VERSION ""

NS_ :

BS_:

BU_:
VAL_TABLE_ FMI 31 "Not available" 19 "Received network data in error" 18 "Below normal (moderately severe)" 17 "Below normal (least severe)" 16 "Above normal (moderately severe)" 15 "Above normal (least severe)" 14 "Special intstructions" 13 "Out of calibration" 12 "Bad intelligent device" 11 "Root cause not known" 10 "Abnormal rate of change" 9 "Abnormal update rate" 8 "Abnormal frequency" 7 "Mechanical system not responding" 6 "Current above normal" 5 "Current below normal" 4 "Voltage below normal" 3 "Voltage above normal" 2 "Data erratic" 1 "Below normal (most severe)" 0 "Above normal (most severe)" ;

BO_ 3221225472 VECTOR__INDEPENDENT_SIG_MSG: 0 Vector__XXX
 SG_ DslPrtcltFltrActvRgnrtnInhbtdDTE : 0|2@1+ (1,0) [0|3] "" Vector__XXX
 SG_ DTC1 : 0|32@1+ (1,0) [0|4294967295] "" Vector__XXX
 SG_ TestIdentifier : 0|8@1+ (1,0) [1|64] "" Vector__XXX
 SG_ TestIdentifier : 0|8@1+ (1,0) [1|64] "" Vector__XXX

BO_ 257 CANSTD2: 8 Vector__XXX

BO_ 2147548747 CANEXT4: 2 Vector__XXX
 SG_ EXT4_sig : 0|2@1+ (1,0) [0|0] "" Vector__XXX

BO_ 2147483904 CANEXT3: 8 Vector__XXX
 SG_ EXT3_sig : 0|8@1+ (1,0) [0|0] "" Vector__XXX

BO_ 256 CANSTD1: 8 Vector__XXX
 SG_ STD1_sig : 0|2@1+ (1,0) [0|0] "" Vector__XXX

BO_ 2298366974 CANEXT2: 2 Vector__XXX
 SG_ EXT2_sig : 0|2@1+ (1,0) [0|0] "" Vector__XXX

BO_ 2224684798 CANEXT1: 8 Vector__XXX
 SG_ EXT1_sig : 0|8@1+ (1,0) [0|0] "" Vector__XXX

BO_ 2348941054 TC1: 8 Vector__XXX
 SG_ TransMode8 : 62|2@1+ (1,0) [0|3] "" Vector__XXX
 SG_ TransMode7 : 60|2@1+ (1,0) [0|3] "" Vector__XXX
 SG_ TransMode6 : 58|2@1+ (1,0) [0|3] "" Vector__XXX
 SG_ TransMode5 : 56|2@1+ (1,0) [0|3] "" Vector__XXX
 SG_ TrnsShftSlectorDisplayModeSwitch : 54|2@1+ (1,0) [0|3] "" Vector__XXX
 SG_ TransRequestedLaunchGear : 50|4@1+ (1,0) [0|15] "" Vector__XXX
 SG_ TransMode4 : 46|2@1+ (1,0) [0|3] "" Vector__XXX
 SG_ TransMode3 : 44|2@1+ (1,0) [0|3] "" Vector__XXX
 SG_ TransMode2 : 42|2@1+ (1,0) [0|3] "" Vector__XXX
 SG_ TransMode1 : 40|2@1+ (1,0) [0|3] "" Vector__XXX
 SG_ DisengageDiffLockRqCentralRear : 36|2@1+ (1,0) [0|3] "" Vector__XXX
 SG_ DisengageDiffLockRqCentralFront : 34|2@1+ (1,0) [0|3] "" Vector__XXX
 SG_ DisengageDiffLockRqCentral : 32|2@1+ (1,0) [0|3] "" Vector__XXX
 SG_ DisengageDiffLockRqRearAxle2 : 30|2@1+ (1,0) [0|3] "" Vector__XXX
 SG_ DisengageDiffLockRqRearAxle1 : 28|2@1+ (1,0) [0|3] "" Vector__XXX
 SG_ DisengageDiffLockRqFrontAxle2 : 26|2@1+ (1,0) [0|3] "" Vector__XXX
 SG_ DisengageDiffLockRqFrontAxle1 : 24|2@1+ (1,0) [0|3] "" Vector__XXX
 SG_ TransRequestedGear : 16|8@1+ (1,-125) [-125|125] "" Vector__XXX
 SG_ RequestedPercentClutchSlip : 8|8@1+ (1,0) [0|100] "%" Vector__XXX
 SG_ TransReverseGearShiftInhibitRq : 6|2@1+ (1,0) [0|3] "" Vector__XXX
 SG_ DisengageDrivelineRq : 4|2@1+ (1,0) [0|3] "" Vector__XXX
 SG_ TrnsTrqeConverterLockupDisableRq : 2|2@1+ (1,0) [0|3] "" Vector__XXX
 SG_ TransGearShiftInhibitRq : 0|2@1+ (1,0) [0|3] "" Vector__XXX

BO_ 2358902526 JLCM: 8 Vector__XXX
 SG_ Joystick3Lamp10Cmd : 58|2@1+ (1,0) [0|3] "" Vector__XXX
 SG_ Joystick3Lamp9Cmd : 56|2@1+ (1,0) [0|3] "" Vector__XXX
 SG_ Joystick3Lamp8Cmd : 54|2@1+ (1,0) [0|3] "" Vector__XXX
 SG_ Joystick3Lamp7Cmd : 52|2@1+ (1,0) [0|3] "" Vector__XXX
 SG_ Joystick3Lamp6Cmd : 50|2@1+ (1,0) [0|3] "" Vector__XXX
 SG_ Joystick3Lamp5Cmd : 48|2@1+ (1,0) [0|3] "" Vector__XXX
 SG_ Joystick3Lamp4Cmd : 46|2@1+ (1,0) [0|3] "" Vector__XXX
 SG_ Joystick3Lamp3Cmd : 44|2@1+ (1,0) [0|3] "" Vector__XXX
 SG_ Joystick3Lamp2Cmd : 42|2@1+ (1,0) [0|3] "" Vector__XXX
 SG_ Joystick3Lamp1Cmd : 40|2@1+ (1,0) [0|3] "" Vector__XXX
 SG_ Joystick2Lamp10Cmd : 38|2@1+ (1,0) [0|3] "" Vector__XXX
 SG_ Joystick2Lamp9Cmd : 36|2@1+ (1,0) [0|3] "" Vector__XXX
 SG_ Joystick2Lamp8Cmd : 34|2@1+ (1,0) [0|3] "" Vector__XXX
 SG_ Joystick2Lamp7Cmd : 32|2@1+ (1,0) [0|3] "" Vector__XXX
 SG_ Joystick2Lamp6Cmd : 30|2@1+ (1,0) [0|3] "" Vector__XXX
 SG_ Joystick2Lamp5Cmd : 28|2@1+ (1,0) [0|3] "" Vector__XXX
 SG_ Joystick2Lamp4Cmd : 26|2@1+ (1,0) [0|3] "" Vector__XXX
 SG_ Joystick2Lamp3Cmd : 24|2@1+ (1,0) [0|3] "" Vector__XXX
 SG_ Joystick2Lamp2Cmd : 22|2@1+ (1,0) [0|3] "" Vector__XXX
 SG_ Joystick2Lamp1Cmd : 20|2@1+ (1,0) [0|3] "" Vector__XXX
 SG_ Joystick1Lamp10Cmd : 18|2@1+ (1,0) [0|3] "" Vector__XXX
 SG_ Joystick1Lamp9Cmd : 16|2@1+ (1,0) [0|3] "" Vector__XXX
 SG_ Joystick1Lamp8Cmd : 14|2@1+ (1,0) [0|3] "" Vector__XXX
 SG_ Joystick1Lamp7Cmd : 12|2@1+ (1,0) [0|3] "" Vector__XXX
 SG_ Joystick1Lamp6Cmd : 10|2@1+ (1,0) [0|3] "" Vector__XXX
 SG_ Joystick1Lamp5Cmd : 8|2@1+ (1,0) [0|3] "" Vector__XXX
 SG_ Joystick1Lamp4Cmd : 6|2@1+ (1,0) [0|3] "" Vector__XXX
 SG_ Joystick1Lamp3Cmd : 4|2@1+ (1,0) [0|3] "" Vector__XXX
 SG_ Joystick1Lamp2Cmd : 2|2@1+ (1,0) [0|3] "" Vector__XXX
 SG_ Joystick1Lamp1Cmd : 0|2@1+ (1,0) [0|3] "" Vector__XXX

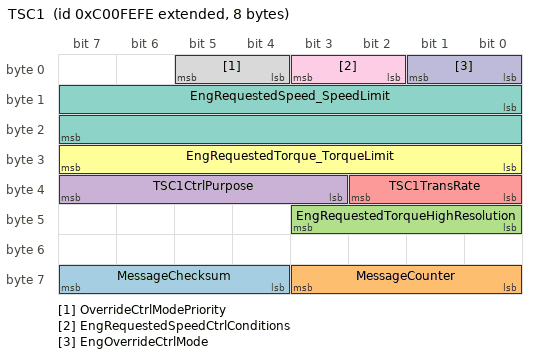
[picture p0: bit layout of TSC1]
BO_ 2348875518 TSC1: 8 Vector__XXX
 SG_ MessageChecksum : 60|4@1+ (1,0) [0|15] "" Vector__XXX
 SG_ MessageCounter : 56|4@1+ (1,0) [0|15] "" Vector__XXX
 SG_ EngRequestedTorqueHighResolution : 40|4@1+ (1,0) [0|0.875] "%" Vector__XXX
 SG_ TSC1CtrlPurpose : 35|5@1+ (1,0) [0|31] "" Vector__XXX
 SG_ TSC1TransRate : 32|3@1+ (1,0) [0|7] "" Vector__XXX
 SG_ EngRequestedTorque_TorqueLimit : 24|8@1+ (1,-125) [-125|125] "%" Vector__XXX
 SG_ EngRequestedSpeed_SpeedLimit : 8|16@1+ (1,0) [0|8031.875] "rpm" Vector__XXX
 SG_ OverrideCtrlModePriority : 4|2@1+ (1,0) [0|3] "" Vector__XXX
 SG_ EngRequestedSpeedCtrlConditions : 2|2@1+ (1,0) [0|3] "" Vector__XXX
 SG_ EngOverrideCtrlMode : 0|2@1+ (1,0) [0|3] "" Vector__XXX

BO_ 2566802430 TCFG2: 2 Vector__XXX
 SG_ TransTorqueLimit : 0|16@1+ (1,0) [0|64255] "Nm" Vector__XXX

BO_ 2566841342 EC1: 39 Vector__XXX
 SG_ SupportTSC1CtrlPurposeGroup4 : 304|8@1+ (1,0) [0|255] "" Vector__XXX
 SG_ SupportTSC1CtrlPurposeGroup3 : 296|8@1+ (1,0) [0|255] "" Vector__XXX
 SG_ SupportTSC1CtrlPurposeGroup2 : 288|8@1+ (1,0) [0|255] "" Vector__XXX
 SG_ SupportTSC1CtrlPurposeGroup1 : 280|8@1+ (1,0) [0|255] "" Vector__XXX
 SG_ SupportVariableRateTSC1Message : 272|8@1+ (1,0) [0|255] "" Vector__XXX
 SG_ EngDefaultTorqueLimit : 256|16@1+ (1,0) [0|64255] "Nm" Vector__XXX
 SG_ EngMomentOfInertia : 240|16@1+ (0.004,0) [0|262.14] "kg-m^2" Vector__XXX
 SG_ EngExRngRqstdSpdCtrlRngUpprLimit : 224|16@1+ (0.125,0) [0|8031.875] "rpm" Vector__XXX
 SG_ EngRqstdTrqueCtrlRangeUpperLimit : 216|8@1+ (1,-125) [-125|125] "%" Vector__XXX
 SG_ EngRqstdTrqueCtrlRangeLowerLimit : 208|8@1+ (1,-125) [-125|125] "%" Vector__XXX
 SG_ EngRqstdSpeedCtrlRangeUpperLimit : 200|8@1+ (10,0) [0|2500] "rpm" Vector__XXX
 SG_ EngRqstdSpeedCtrlRangeLowerLimit : 192|8@1+ (10,0) [0|2500] "rpm" Vector__XXX
 SG_ EngMaxMomentaryOverrideTimeLimit : 184|8@1+ (0.1,0) [0|25] "s" Vector__XXX
 SG_ EngMxMmentaryOverrideSpeedPoint7 : 168|16@1+ (0.125,0) [0|8031.875] "rpm" Vector__XXX
 SG_ EngReferenceTorque : 152|16@1+ (1,0) [0|64255] "Nm" Vector__XXX
 SG_ EngGain : 136|16@1+ (0.00078126215858688,0) [0|50.2] "%/rpm" Vector__XXX
 SG_ EngSpeedAtHighIdlePoint6 : 120|16@1+ (0.125,0) [0|8031.875] "rpm" Vector__XXX
 SG_ EngPercentTorqueAtPoint5 : 112|8@1+ (1,-125) [-125|125] "%" Vector__XXX
 SG_ EngSpeedAtPoint5 : 96|16@1+ (0.125,0) [0|8031.875] "rpm" Vector__XXX
 SG_ EngPercentTorqueAtPoint4 : 88|8@1+ (1,-125) [-125|125] "%" Vector__XXX
 SG_ EngSpeedAtPoint4 : 72|16@1+ (0.125,0) [0|8031.875] "rpm" Vector__XXX
 SG_ EngPercentTorqueAtPoint3 : 64|8@1+ (1,-125) [-125|125] "%" Vector__XXX
 SG_ EngSpeedAtPoint3 : 48|16@1+ (0.125,0) [0|8031.875] "rpm" Vector__XXX
 SG_ EngPercentTorqueAtPoint2 : 40|8@1+ (1,-125) [-125|125] "%" Vector__XXX
 SG_ EngSpeedAtPoint2 : 24|16@1+ (0.125,0) [0|8031.875] "rpm" Vector__XXX
 SG_ EngPercentTorqueAtIdlePoint1 : 16|8@1+ (1,-125) [-125|125] "%" Vector__XXX
 SG_ EngSpeedAtIdlePoint1 : 0|16@1+ (0.125,0) [0|8031.875] "rpm" Vector__XXX

BO_ 2564030206 DM19: 20 Vector__XXX
 SG_ CalibrationID4 : 128|32@1+ (1,0) [0|4294967295] "" Vector__XXX
 SG_ CalibrationID3 : 96|32@1+ (1,0) [0|4294967295] "" Vector__XXX
 SG_ CalibrationID2 : 64|32@1+ (1,0) [0|4294967295] "" Vector__XXX
 SG_ CalibrationID1 : 32|32@1+ (1,0) [0|4294967295] "" Vector__XXX
 SG_ CalibrationVerificationNumber : 0|32@1+ (1,0) [0|4294967295] "" Vector__XXX

CM_ BO_ 3221225472 "This is a message for not used signals, created by Vector CANdb++ DBC OLE DB Provider.";
CM_ SG_ 3221225472 DslPrtcltFltrActvRgnrtnInhbtdDTE "Indicates the state of diesel particulate filter active regeneration inhibition due to the engine not being warmed up.";
CM_ SG_ 3221225472 DTC1 "Diagnostic Trouble CodeDiagnostic Trouble CodeDiagnostic Trouble CodeDiagnostic Trouble CodeDiagnostic Trouble CodeDiagnostic Trouble CodeDiagnostic Trouble CodeDiagnostic Trouble CodeDiagnostic Trouble CodeDiagnostic Trouble CodeDiagnostic Trouble CodeDiagnostic Trouble CodeDiagnostic Trouble CodeDiagnostic Trouble CodeDiagnostic Trouble CodeDiagnostic Trouble CodeDiagnostic Trouble CodeDiagnostic Trouble CodeDiagnostic Trouble CodeDiagnostic Trouble CodeDiagnostic Trouble CodeDiagnostic Trouble CodeDiagnostic Trouble Code";
CM_ BO_ 257 "Msg without signal";
CM_ BO_ 2147548747 "CAN ext, near PGN 0xFE4B";
CM_ BO_ 2147483904 "CAN ext, near PGN 0x100";
CM_ BO_ 256 "CAN std, near PGN 0x100";
CM_ BO_ 2298366974 "CAN ext, near TCFG2";
CM_ BO_ 2224684798 "CAN ext, near JLCM";
CM_ SG_ 2348941054 TransMode8 "Indicates whether transmission mode 8 is enabled. Modes are manufacturer specific and are not necessarily mutually";
CM_ SG_ 2348941054 TransMode7 "Indicates whether transmission mode 7 is enabled. Modes are manufacturer specific and are not necessarily mutually";
CM_ SG_ 2348941054 TransMode6 "Indicates whether transmission mode 6 is enabled. Modes are manufacturer specific and are not necessarily mutually";
CM_ SG_ 2348941054 TransMode5 "Indicates whether transmission mode 5 is enabled. Modes are manufacturer specific and are not necessarily mutually";
CM_ SG_ 2348941054 TrnsShftSlectorDisplayModeSwitch "Status of the operator’s switch used to ‘toggle’ through multiple display modes of a shift selector display.";
CM_ SG_ 2348941054 TransRequestedLaunchGear "Initial gear for the transmission to start out in when the vehicle is launched from a standing stop, as specified by the";
CM_ SG_ 2348941054 TransMode4 "Indicates whether transmission mode 4 is enabled. Modes are manufacturer specific and are not necessarily mutually";
CM_ SG_ 2348941054 TransMode3 "Indicates whether transmission mode 3 is enabled. Modes are manufacturer specific and are not necessarily mutually";
CM_ SG_ 2348941054 TransMode2 "Indicates whether transmission mode 2 is enabled. Modes are manufacturer specific and are not necessarily mutually";
CM_ SG_ 2348941054 TransMode1 "Indicates whether transmission mode 1 is enabled. Modes are manufacturer specific and are not necessarily mutually";
CM_ SG_ 2348941054 DisengageDiffLockRqCentralRear "Command signal used to disengage the various differential locks, e.g., to allow an undistributed individual wheel control";
CM_ SG_ 2348941054 DisengageDiffLockRqCentralFront "Command signal used to disengage the various differential locks, e.g., to allow an undistributed individual wheel control";
CM_ SG_ 2348941054 DisengageDiffLockRqCentral "Command signal used to disengage the various differential locks, e.g., to allow an undistributed individual wheel control";
CM_ SG_ 2348941054 DisengageDiffLockRqRearAxle2 "Command signal used to disengage the various differential locks, e.g., to allow an undistributed individual wheel control";
CM_ SG_ 2348941054 DisengageDiffLockRqRearAxle1 "Command signal used to disengage the various differential locks, e.g., to allow an undistributed individual wheel control";
CM_ SG_ 2348941054 DisengageDiffLockRqFrontAxle2 "Command signal used to disengage the various differential locks, e.g., to allow an undistributed individual wheel control";
CM_ SG_ 2348941054 DisengageDiffLockRqFrontAxle1 "Command signal used to disengage the various differential locks, e.g., to allow an undistributed individual wheel control";
CM_ SG_ 2348941054 TransRequestedGear "Gear requested by the operator, ABS, or engine.";
CM_ SG_ 2348941054 RequestedPercentClutchSlip "Parameter which represents the percent clutch slip requested by a device.";
CM_ SG_ 2348941054 TransReverseGearShiftInhibitRq "Allows devices external to the normal transmission shift selector system to request the transmission to inhibit shifts into";
CM_ SG_ 2348941054 DisengageDrivelineRq "Command signal used to simply disengage the driveline, e.g., to prevent engine drag torque from causing high wheel slip";
CM_ SG_ 2348941054 TrnsTrqeConverterLockupDisableRq "Command signal to prevent torque converter lockup, which may cause problems in certain circumstances for ASR.";
CM_ SG_ 2348941054 TransGearShiftInhibitRq "Command signal to inhibit gear shifts.";
CM_ BO_ 2358902526 "Used to transfer joystick lamp command informations which are used to switch on/off/blinking joystick 1...3 lamps 1...10.";
CM_ SG_ 2358902526 Joystick3Lamp10Cmd "Tells joystick 3 to switch on/off/blinking lamp 10.";
CM_ SG_ 2358902526 Joystick3Lamp9Cmd "Tells joystick 3 to switch on/off/blinking lamp 9.";
CM_ SG_ 2358902526 Joystick3Lamp8Cmd "Tells joystick 3 to switch on/off/blinking lamp 8.";
CM_ SG_ 2358902526 Joystick3Lamp7Cmd "Tells joystick 3 to switch on/off/blinking lamp 7.";
CM_ SG_ 2358902526 Joystick3Lamp6Cmd "Tells joystick 3 to switch on/off/blinking lamp 6.";
CM_ SG_ 2358902526 Joystick3Lamp5Cmd "Tells joystick 3 to switch on/off/blinking lamp 5.";
CM_ SG_ 2358902526 Joystick3Lamp4Cmd "Tells joystick 3 to switch on/off/blinking lamp 4.";
CM_ SG_ 2358902526 Joystick3Lamp3Cmd "Tells joystick 3 to switch on/off/blinking lamp 3.";
CM_ SG_ 2358902526 Joystick3Lamp2Cmd "Tells joystick 3 to switch on/off/blinking lamp 2.";
CM_ SG_ 2358902526 Joystick3Lamp1Cmd "Tells joystick 3 to switch on/off/blinking lamp 1.";
CM_ SG_ 2358902526 Joystick2Lamp10Cmd "Tells joystick 2 to switch on/off/blinking lamp 10.";
CM_ SG_ 2358902526 Joystick2Lamp9Cmd "Tells joystick 2 to switch on/off/blinking lamp 9.";
CM_ SG_ 2358902526 Joystick2Lamp8Cmd "Tells joystick 2 to switch on/off/blinking lamp 8.";
CM_ SG_ 2358902526 Joystick2Lamp7Cmd "Tells joystick 2 to switch on/off/blinking lamp 7.";
CM_ SG_ 2358902526 Joystick2Lamp6Cmd "Tells joystick 2 to switch on/off/blinking lamp 6.";
CM_ SG_ 2358902526 Joystick2Lamp5Cmd "Tells joystick 2 to switch on/off/blinking lamp 5.";
CM_ SG_ 2358902526 Joystick2Lamp4Cmd "Tells joystick 2 to switch on/off/blinking lamp 4.";
CM_ SG_ 2358902526 Joystick2Lamp3Cmd "Tells joystick 2 to switch on/off/blinking lamp 3.";
CM_ SG_ 2358902526 Joystick2Lamp2Cmd "Tells joystick 2 to switch on/off/blinking lamp 2.";
CM_ SG_ 2358902526 Joystick2Lamp1Cmd "Tells joystick 2 to switch on/off/blinking lamp 1.";
CM_ SG_ 2358902526 Joystick1Lamp10Cmd "Tells joystick 1 to switch on/off/blinking lamp 10.";
CM_ SG_ 2358902526 Joystick1Lamp9Cmd "Tells joystick 1 to switch on/off/blinking lamp 9.";
CM_ SG_ 2358902526 Joystick1Lamp8Cmd "Tells joystick 1 to switch on/off/blinking lamp 8.";
CM_ SG_ 2358902526 Joystick1Lamp7Cmd "Tells joystick 1 to switch on/off/blinking lamp 7.";
CM_ SG_ 2358902526 Joystick1Lamp6Cmd "Tells joystick 1 to switch on/off/blinking lamp 6.";
CM_ SG_ 2358902526 Joystick1Lamp5Cmd "Tells joystick 1 to switch on/off/blinking lamp 5.";
CM_ SG_ 2358902526 Joystick1Lamp4Cmd "Tells joystick 1 to switch on/off/blinking lamp 4.";
CM_ SG_ 2358902526 Joystick1Lamp3Cmd "Tells joystick 1 to switch on/off/blinking lamp 3.";
CM_ SG_ 2358902526 Joystick1Lamp2Cmd "Tells joystick 1 to switch on/off/blinking lamp 2.";
CM_ SG_ 2358902526 Joystick1Lamp1Cmd "Tells joystick 1 to switch on/off/blinking lamp 1.";
CM_ BO_ 2348875518 "NOTE - Retarder may be disabled by commanding a torque limit of 0%. Use of the limit mode allows the use of the";
CM_ SG_ 2348875518 MessageChecksum "The message checksum is used to verify the signal path from the transmitting device to the receiving device.";
CM_ SG_ 2348875518 MessageCounter "The message counter is used to detect situations where the transmitting ECU malfunction repeats the same frame all the";
CM_ SG_ 2348875518 EngRequestedTorqueHighResolution "This parameter displays an additional torque in percent of the reference engine torque.";
CM_ SG_ 2348875518 TSC1CtrlPurpose "State signal which indicates which control mode the sending device is using to generate the TSC1 command. Note that";
CM_ SG_ 2348875518 TSC1TransRate "This parameter indicates the transmission rate at which the sending device will transmit the TSC1 message. The engine";
CM_ SG_ 2348875518 EngRequestedTorque_TorqueLimit "Parameter provided to the engine or retarder in the torque/speed control message for controlling or limiting the output";
CM_ SG_ 2348875518 EngRequestedSpeed_SpeedLimit "Parameter provided to the engine from external sources in the torque/speed control message. This is the engine speed";
CM_ SG_ 2348875518 OverrideCtrlModePriority "This field is used as an input to the engine or retarder to determine the priority of the Override Control Mode received in";
CM_ SG_ 2348875518 EngRequestedSpeedCtrlConditions "This mode tells the engine control system the governor characteristics that are desired during speed control. The four";
CM_ SG_ 2348875518 EngOverrideCtrlMode "The override control mode defines which sort of command is used:";
CM_ BO_ 2566802430 "Transmission Configuration 2";
CM_ SG_ 2566802430 TransTorqueLimit "Parameter provided to the engine from the transmission as a torque limit to be invoked by the engine in the event that";
CM_ BO_ 2566841342 "This map describes the stationary behavior of the engine and the speed dependent available indicated torque. This map";
CM_ SG_ 2566841342 SupportTSC1CtrlPurposeGroup4 "This parameter indicates which TSC1 control purposes are supported in group 4 of 4. One bit is used to convey the";
CM_ SG_ 2566841342 SupportTSC1CtrlPurposeGroup3 "This parameter indicates which TSC1 control purposes are supported in group 3 of 4. One bit is used to convey the";
CM_ SG_ 2566841342 SupportTSC1CtrlPurposeGroup2 "This parameter indicates which TSC1 control purposes are supported in group 2 of 4. One bit is used to convey the";
CM_ SG_ 2566841342 SupportTSC1CtrlPurposeGroup1 "This parameter indicates which TSC1 control purposes are supported in group 1 of 4. One bit is used to convey the";
CM_ SG_ 2566841342 SupportVariableRateTSC1Message "This parameter indicates which TSC1 transmission rates are supported by the engine ECU in addition to the required";
CM_ SG_ 2566841342 EngDefaultTorqueLimit "Companion parameter to Transmission Torque Limit (SPN 1845). This “echo” parameter provides confirmation to the";
CM_ SG_ 2566841342 EngMomentOfInertia "Moment of inertia for the engine, including items driven full-time by the engine such as fuel, oil and cooling pumps. The";
CM_ SG_ 2566841342 EngExRngRqstdSpdCtrlRngUpprLimit "The maximum engine speed regardless of load that the engine will allow when operating in a speed control/limit mode,";
CM_ SG_ 2566841342 EngRqstdTrqueCtrlRangeUpperLimit "The maximum engine torque that the engine will allow when operating in a torque control/limit mode.";
CM_ SG_ 2566841342 EngRqstdTrqueCtrlRangeLowerLimit "The minimum engine torque that the engine will allow when operating in a torque control/limit mode.";
CM_ SG_ 2566841342 EngRqstdSpeedCtrlRangeUpperLimit "The maximum engine speed regardless of load that the engine will allow when operating in a speed control/limit mode,";
CM_ SG_ 2566841342 EngRqstdSpeedCtrlRangeLowerLimit "The minimum engine speed that the engine will allow when operating in a speed control/limit mode.";
CM_ SG_ 2566841342 EngMaxMomentaryOverrideTimeLimit "The maximum time limit allowed to override the engine's high idle speed.";
CM_ SG_ 2566841342 EngMxMmentaryOverrideSpeedPoint7 "The maximum engine speed above high idle allowed by the engine control during a momentary high idle override. This";
CM_ SG_ 2566841342 EngReferenceTorque "This parameter is the 100% reference value for all defined indicated engine torque parameters. It is only defined once";
CM_ SG_ 2566841342 EngGain "The endspeed governor is defined as a linear line with the following equations (Capital letters mean physical values, small";
CM_ SG_ 2566841342 EngSpeedAtHighIdlePoint6 "Engine speed of high idle (point 6) of the engine torque map (see PGN 65251 and supporting document). In engine";
CM_ SG_ 2566841342 EngPercentTorqueAtPoint5 "The torque limit that indicates the available engine torque which can be provided by the engine at point 3, 4, and 5 of the";
CM_ SG_ 2566841342 EngSpeedAtPoint5 "Engine speed of point 3, 4, and 5 of the engine torque map (see PGN 65251 and supporting document). It is";
CM_ SG_ 2566841342 EngPercentTorqueAtPoint4 "The torque limit that indicates the available engine torque which can be provided by the engine at point 3, 4, and 5 of the";
CM_ SG_ 2566841342 EngSpeedAtPoint4 "Engine speed of point 3, 4, and 5 of the engine torque map (see PGN 65251 and supporting document). It is";
CM_ SG_ 2566841342 EngPercentTorqueAtPoint3 "The torque limit that indicates the available engine torque which can be provided by the engine at point 3, 4, and 5 of the";
CM_ SG_ 2566841342 EngSpeedAtPoint3 "Engine speed of point 3, 4, and 5 of the engine torque map (see PGN 65251 and supporting document). It is";
CM_ SG_ 2566841342 EngPercentTorqueAtPoint2 "The torque limit that indicates the available engine torque which can be provided by the engine at point 2 of the engine";
CM_ SG_ 2566841342 EngSpeedAtPoint2 "Engine speed of point 2 of the engine torque map (see PGN 65251 and supporting document). In engine configuration";
CM_ SG_ 2566841342 EngPercentTorqueAtIdlePoint1 "The torque limit that indicates the available engine torque which can be provided by the engine at idle speed. This";
CM_ SG_ 2566841342 EngSpeedAtIdlePoint1 "Stationary low idle speed of engine which includes influences due to engine temperature (after power up) and other";
CM_ BO_ 2564030206 "Calibration Information";
BA_DEF_ SG_  "SigType" ENUM  "Default","Range","RangeSigned","ASCII","Discrete","Control","ReferencePGN","DTC","StringDelimiter","StringLength","StringLengthControl";
BA_DEF_ SG_  "GenSigSendType" ENUM  "Cyclic","OnWrite","reserved","OnChange","reserved","reserved","reserved","NoSigSendType";
BA_DEF_ SG_  "GenSigILSupport" ENUM  "Yes","No";
BA_DEF_ SG_  "GenSigEVName" STRING ;
BA_DEF_ SG_  "SPN" INT 0 524287;
BA_DEF_ SG_  "SAEDocument" STRING ;
BA_DEF_ BO_  "GenMsgILSupport" ENUM  "Yes","No";
BA_DEF_ BO_  "GenMsgRequestable" INT 0 1;
BA_DEF_ BO_  "GenMsgSendType" ENUM  "cyclic","reserved","cyclicIfActive","reserved","reserved","reserved","reserved","reserved","noMsgSendType";
BA_DEF_ BO_  "VFrameFormat" ENUM  "StandardCAN","ExtendedCAN","reserved","J1939PG";
BA_DEF_ BO_  "SingleFrame" INT 0 1;
BA_DEF_ BO_  "GenMsgCycleTime" INT 0 3600000;
BA_DEF_ BO_  "SAE_Document" STRING ;
BA_DEF_ BU_  "NmStationAddress" INT 0 255;
BA_DEF_  "DatabaseVersion" STRING ;
BA_DEF_  "BusType" STRING ;
BA_DEF_  "ProtocolType" STRING ;
BA_DEF_  "SAE_J1939_75_SpecVersion" STRING ;
BA_DEF_  "SAE_J1939_21_SpecVersion" STRING ;
BA_DEF_  "SAE_J1939_73_SpecVersion" STRING ;
BA_DEF_  "SAE_J1939_71_SpecVersion" STRING ;
BA_DEF_ SG_  "SystemSignalLongSymbol" STRING ;
BA_DEF_DEF_  "SigType" "Default";
BA_DEF_DEF_  "GenSigSendType" "NoSigSendType";
BA_DEF_DEF_  "GenSigILSupport" "Yes";
BA_DEF_DEF_  "GenSigEVName" "Env@Nodename_@Signame";
BA_DEF_DEF_  "SPN" 0;
BA_DEF_DEF_  "SAEDocument" "";
BA_DEF_DEF_  "GenMsgILSupport" "Yes";
BA_DEF_DEF_  "GenMsgRequestable" 1;
BA_DEF_DEF_  "GenMsgSendType" "noMsgSendType";
BA_DEF_DEF_  "VFrameFormat" "J1939PG";
BA_DEF_DEF_  "SingleFrame" 1;
BA_DEF_DEF_  "GenMsgCycleTime" 0;
BA_DEF_DEF_  "SAE_Document" "";
BA_DEF_DEF_  "NmStationAddress" 254;
BA_DEF_DEF_  "DatabaseVersion" "";
BA_DEF_DEF_  "BusType" "";
BA_DEF_DEF_  "ProtocolType" "";
BA_DEF_DEF_  "SAE_J1939_75_SpecVersion" "";
BA_DEF_DEF_  "SAE_J1939_21_SpecVersion" "";
BA_DEF_DEF_  "SAE_J1939_73_SpecVersion" "";
BA_DEF_DEF_  "SAE_J1939_71_SpecVersion" "";
BA_DEF_DEF_  "SystemSignalLongSymbol" "";
BA_ "DatabaseVersion" "7.5";
BA_ "BusType" "CAN";
BA_ "ProtocolType" "J1939";
BA_ "SAE_J1939_75_SpecVersion" "2005-10";
BA_ "SAE_J1939_21_SpecVersion" "2006-10";
BA_ "SAE_J1939_73_SpecVersion" "2010-10";
BA_ "SAE_J1939_71_SpecVersion" "2010-10";
BA_ "VFrameFormat" BO_ 257 0;
BA_ "VFrameFormat" BO_ 2147548747 1;
BA_ "VFrameFormat" BO_ 2147483904 1;
BA_ "VFrameFormat" BO_ 256 0;
BA_ "VFrameFormat" BO_ 2298366974 1;
BA_ "VFrameFormat" BO_ 2224684798 1;
BA_ "SAE_Document" BO_ 2348941054 "J1939-71";
BA_ "GenMsgCycleTime" BO_ 2348941054 50;
BA_ "GenMsgSendType" BO_ 2348941054 2;
BA_ "GenMsgSendType" BO_ 2358902526 0;
BA_ "GenMsgCycleTime" BO_ 2358902526 100;
BA_ "SAE_Document" BO_ 2358902526 "J1939-71";
BA_ "GenMsgSendType" BO_ 2348875518 0;
BA_ "GenMsgCycleTime" BO_ 2348875518 10;
BA_ "SAE_Document" BO_ 2348875518 "J1939-71";
BA_ "SAE_Document" BO_ 2566802430 "J1939-71";
BA_ "GenMsgSendType" BO_ 2566841342 0;
BA_ "GenMsgCycleTime" BO_ 2566841342 5000;
BA_ "SAE_Document" BO_ 2566841342 "J1939-71";
BA_ "SAE_Document" BO_ 2564030206 "J1939-73";
BA_ "SigType" SG_ 3221225472 DslPrtcltFltrActvRgnrtnInhbtdDTE 4;
BA_ "SPN" SG_ 3221225472 DslPrtcltFltrActvRgnrtnInhbtdDTE 3716;
BA_ "SAEDocument" SG_ 3221225472 DslPrtcltFltrActvRgnrtnInhbtdDTE "J1939-71";
BA_ "SystemSignalLongSymbol" SG_ 3221225472 DslPrtcltFltrActvRgnrtnInhbtdDTE "DslPrtcltFltrActvRgnrtnInhbtdDTEngNtWrmdUp";
BA_ "SigType" SG_ 3221225472 DTC1 7;
BA_ "SAEDocument" SG_ 3221225472 DTC1 "J1939-73";
BA_ "SigType" SG_ 2348941054 TransMode8 5;
BA_ "SPN" SG_ 2348941054 TransMode8 4249;
BA_ "SAEDocument" SG_ 2348941054 TransMode8 "J1939-71";
BA_ "SigType" SG_ 2348941054 TransMode7 5;
BA_ "SPN" SG_ 2348941054 TransMode7 4248;
BA_ "SAEDocument" SG_ 2348941054 TransMode7 "J1939-71";
BA_ "SigType" SG_ 2348941054 TransMode6 5;
BA_ "SPN" SG_ 2348941054 TransMode6 4247;
BA_ "SAEDocument" SG_ 2348941054 TransMode6 "J1939-71";
BA_ "SigType" SG_ 2348941054 TransMode5 5;
BA_ "SPN" SG_ 2348941054 TransMode5 4246;
BA_ "SAEDocument" SG_ 2348941054 TransMode5 "J1939-71";
BA_ "SigType" SG_ 2348941054 TrnsShftSlectorDisplayModeSwitch 4;
BA_ "SPN" SG_ 2348941054 TrnsShftSlectorDisplayModeSwitch 2985;
BA_ "SAEDocument" SG_ 2348941054 TrnsShftSlectorDisplayModeSwitch "J1939-71";
BA_ "SPN" SG_ 2348941054 TransRequestedLaunchGear 4255;
BA_ "SAEDocument" SG_ 2348941054 TransRequestedLaunchGear "J1939-71";
BA_ "SigType" SG_ 2348941054 TransMode4 5;
BA_ "SPN" SG_ 2348941054 TransMode4 1855;
BA_ "SAEDocument" SG_ 2348941054 TransMode4 "J1939-71";
BA_ "SigType" SG_ 2348941054 TransMode3 5;
BA_ "SPN" SG_ 2348941054 TransMode3 1854;
BA_ "SAEDocument" SG_ 2348941054 TransMode3 "J1939-71";
BA_ "SigType" SG_ 2348941054 TransMode2 5;
BA_ "SPN" SG_ 2348941054 TransMode2 1853;
BA_ "SAEDocument" SG_ 2348941054 TransMode2 "J1939-71";
BA_ "SigType" SG_ 2348941054 TransMode1 5;
BA_ "SPN" SG_ 2348941054 TransMode1 1852;
BA_ "SAEDocument" SG_ 2348941054 TransMode1 "J1939-71";
BA_ "SigType" SG_ 2348941054 DisengageDiffLockRqCentralRear 5;
BA_ "SPN" SG_ 2348941054 DisengageDiffLockRqCentralRear 691;
BA_ "SAEDocument" SG_ 2348941054 DisengageDiffLockRqCentralRear "J1939-71";
BA_ "SigType" SG_ 2348941054 DisengageDiffLockRqCentralFront 5;
BA_ "SPN" SG_ 2348941054 DisengageDiffLockRqCentralFront 690;
BA_ "SAEDocument" SG_ 2348941054 DisengageDiffLockRqCentralFront "J1939-71";
BA_ "SigType" SG_ 2348941054 DisengageDiffLockRqCentral 5;
BA_ "SPN" SG_ 2348941054 DisengageDiffLockRqCentral 689;
BA_ "SAEDocument" SG_ 2348941054 DisengageDiffLockRqCentral "J1939-71";
BA_ "SigType" SG_ 2348941054 DisengageDiffLockRqRearAxle2 5;
BA_ "SPN" SG_ 2348941054 DisengageDiffLockRqRearAxle2 688;
BA_ "SAEDocument" SG_ 2348941054 DisengageDiffLockRqRearAxle2 "J1939-71";
BA_ "SigType" SG_ 2348941054 DisengageDiffLockRqRearAxle1 5;
BA_ "SPN" SG_ 2348941054 DisengageDiffLockRqRearAxle1 687;
BA_ "SAEDocument" SG_ 2348941054 DisengageDiffLockRqRearAxle1 "J1939-71";
BA_ "SigType" SG_ 2348941054 DisengageDiffLockRqFrontAxle2 5;
BA_ "SPN" SG_ 2348941054 DisengageDiffLockRqFrontAxle2 686;
BA_ "SAEDocument" SG_ 2348941054 DisengageDiffLockRqFrontAxle2 "J1939-71";
BA_ "SigType" SG_ 2348941054 DisengageDiffLockRqFrontAxle1 5;
BA_ "SPN" SG_ 2348941054 DisengageDiffLockRqFrontAxle1 685;
BA_ "SAEDocument" SG_ 2348941054 DisengageDiffLockRqFrontAxle1 "J1939-71";
BA_ "SPN" SG_ 2348941054 TransRequestedGear 525;
BA_ "SAEDocument" SG_ 2348941054 TransRequestedGear "J1939-71";
BA_ "SPN" SG_ 2348941054 RequestedPercentClutchSlip 684;
BA_ "SAEDocument" SG_ 2348941054 RequestedPercentClutchSlip "J1939-71";
BA_ "SigType" SG_ 2348941054 TransReverseGearShiftInhibitRq 5;
BA_ "SPN" SG_ 2348941054 TransReverseGearShiftInhibitRq 4242;
BA_ "SAEDocument" SG_ 2348941054 TransReverseGearShiftInhibitRq "J1939-71";
BA_ "SigType" SG_ 2348941054 DisengageDrivelineRq 5;
BA_ "SPN" SG_ 2348941054 DisengageDrivelineRq 683;
BA_ "SAEDocument" SG_ 2348941054 DisengageDrivelineRq "J1939-71";
BA_ "SigType" SG_ 2348941054 TrnsTrqeConverterLockupDisableRq 5;
BA_ "SPN" SG_ 2348941054 TrnsTrqeConverterLockupDisableRq 682;
BA_ "SAEDocument" SG_ 2348941054 TrnsTrqeConverterLockupDisableRq "J1939-71";
BA_ "SigType" SG_ 2348941054 TransGearShiftInhibitRq 5;
BA_ "SPN" SG_ 2348941054 TransGearShiftInhibitRq 681;
BA_ "SAEDocument" SG_ 2348941054 TransGearShiftInhibitRq "J1939-71";
BA_ "SigType" SG_ 2358902526 Joystick3Lamp10Cmd 5;
BA_ "SPN" SG_ 2358902526 Joystick3Lamp10Cmd 4489;
BA_ "SAEDocument" SG_ 2358902526 Joystick3Lamp10Cmd "J1939-71";
BA_ "SigType" SG_ 2358902526 Joystick3Lamp9Cmd 5;
BA_ "SPN" SG_ 2358902526 Joystick3Lamp9Cmd 4488;
BA_ "SAEDocument" SG_ 2358902526 Joystick3Lamp9Cmd "J1939-71";
BA_ "SigType" SG_ 2358902526 Joystick3Lamp8Cmd 5;
BA_ "SPN" SG_ 2358902526 Joystick3Lamp8Cmd 4487;
BA_ "SAEDocument" SG_ 2358902526 Joystick3Lamp8Cmd "J1939-71";
BA_ "SigType" SG_ 2358902526 Joystick3Lamp7Cmd 5;
BA_ "SPN" SG_ 2358902526 Joystick3Lamp7Cmd 4486;
BA_ "SAEDocument" SG_ 2358902526 Joystick3Lamp7Cmd "J1939-71";
BA_ "SigType" SG_ 2358902526 Joystick3Lamp6Cmd 5;
BA_ "SPN" SG_ 2358902526 Joystick3Lamp6Cmd 4485;
BA_ "SAEDocument" SG_ 2358902526 Joystick3Lamp6Cmd "J1939-71";
BA_ "SigType" SG_ 2358902526 Joystick3Lamp5Cmd 5;
BA_ "SPN" SG_ 2358902526 Joystick3Lamp5Cmd 4484;
BA_ "SAEDocument" SG_ 2358902526 Joystick3Lamp5Cmd "J1939-71";
BA_ "SigType" SG_ 2358902526 Joystick3Lamp4Cmd 5;
BA_ "SPN" SG_ 2358902526 Joystick3Lamp4Cmd 4483;
BA_ "SAEDocument" SG_ 2358902526 Joystick3Lamp4Cmd "J1939-71";
BA_ "SigType" SG_ 2358902526 Joystick3Lamp3Cmd 5;
BA_ "SPN" SG_ 2358902526 Joystick3Lamp3Cmd 4482;
BA_ "SAEDocument" SG_ 2358902526 Joystick3Lamp3Cmd "J1939-71";
BA_ "SigType" SG_ 2358902526 Joystick3Lamp2Cmd 5;
BA_ "SPN" SG_ 2358902526 Joystick3Lamp2Cmd 4481;
BA_ "SAEDocument" SG_ 2358902526 Joystick3Lamp2Cmd "J1939-71";
BA_ "SigType" SG_ 2358902526 Joystick3Lamp1Cmd 5;
BA_ "SPN" SG_ 2358902526 Joystick3Lamp1Cmd 4480;
BA_ "SAEDocument" SG_ 2358902526 Joystick3Lamp1Cmd "J1939-71";
BA_ "SigType" SG_ 2358902526 Joystick2Lamp10Cmd 5;
BA_ "SPN" SG_ 2358902526 Joystick2Lamp10Cmd 4479;
BA_ "SAEDocument" SG_ 2358902526 Joystick2Lamp10Cmd "J1939-71";
BA_ "SigType" SG_ 2358902526 Joystick2Lamp9Cmd 5;
BA_ "SPN" SG_ 2358902526 Joystick2Lamp9Cmd 4478;
BA_ "SAEDocument" SG_ 2358902526 Joystick2Lamp9Cmd "J1939-71";
BA_ "SigType" SG_ 2358902526 Joystick2Lamp8Cmd 5;
BA_ "SPN" SG_ 2358902526 Joystick2Lamp8Cmd 4477;
BA_ "SAEDocument" SG_ 2358902526 Joystick2Lamp8Cmd "J1939-71";
BA_ "SigType" SG_ 2358902526 Joystick2Lamp7Cmd 5;
BA_ "SPN" SG_ 2358902526 Joystick2Lamp7Cmd 4476;
BA_ "SAEDocument" SG_ 2358902526 Joystick2Lamp7Cmd "J1939-71";
BA_ "SigType" SG_ 2358902526 Joystick2Lamp6Cmd 5;
BA_ "SPN" SG_ 2358902526 Joystick2Lamp6Cmd 4475;
BA_ "SAEDocument" SG_ 2358902526 Joystick2Lamp6Cmd "J1939-71";
BA_ "SigType" SG_ 2358902526 Joystick2Lamp5Cmd 5;
BA_ "SPN" SG_ 2358902526 Joystick2Lamp5Cmd 4474;
BA_ "SAEDocument" SG_ 2358902526 Joystick2Lamp5Cmd "J1939-71";
BA_ "SigType" SG_ 2358902526 Joystick2Lamp4Cmd 5;
BA_ "SPN" SG_ 2358902526 Joystick2Lamp4Cmd 4473;
BA_ "SAEDocument" SG_ 2358902526 Joystick2Lamp4Cmd "J1939-71";
BA_ "SigType" SG_ 2358902526 Joystick2Lamp3Cmd 5;
BA_ "SPN" SG_ 2358902526 Joystick2Lamp3Cmd 4472;
BA_ "SAEDocument" SG_ 2358902526 Joystick2Lamp3Cmd "J1939-71";
BA_ "SigType" SG_ 2358902526 Joystick2Lamp2Cmd 5;
BA_ "SPN" SG_ 2358902526 Joystick2Lamp2Cmd 4471;
BA_ "SAEDocument" SG_ 2358902526 Joystick2Lamp2Cmd "J1939-71";
BA_ "SigType" SG_ 2358902526 Joystick2Lamp1Cmd 5;
BA_ "SPN" SG_ 2358902526 Joystick2Lamp1Cmd 4470;
BA_ "SAEDocument" SG_ 2358902526 Joystick2Lamp1Cmd "J1939-71";
BA_ "SigType" SG_ 2358902526 Joystick1Lamp10Cmd 5;
BA_ "SPN" SG_ 2358902526 Joystick1Lamp10Cmd 4469;
BA_ "SAEDocument" SG_ 2358902526 Joystick1Lamp10Cmd "J1939-71";
BA_ "SigType" SG_ 2358902526 Joystick1Lamp9Cmd 5;
BA_ "SPN" SG_ 2358902526 Joystick1Lamp9Cmd 4468;
BA_ "SAEDocument" SG_ 2358902526 Joystick1Lamp9Cmd "J1939-71";
BA_ "SigType" SG_ 2358902526 Joystick1Lamp8Cmd 5;
BA_ "SPN" SG_ 2358902526 Joystick1Lamp8Cmd 4467;
BA_ "SAEDocument" SG_ 2358902526 Joystick1Lamp8Cmd "J1939-71";
BA_ "SigType" SG_ 2358902526 Joystick1Lamp7Cmd 5;
BA_ "SPN" SG_ 2358902526 Joystick1Lamp7Cmd 4466;
BA_ "SAEDocument" SG_ 2358902526 Joystick1Lamp7Cmd "J1939-71";
BA_ "SigType" SG_ 2358902526 Joystick1Lamp6Cmd 5;
BA_ "SPN" SG_ 2358902526 Joystick1Lamp6Cmd 4465;
BA_ "SAEDocument" SG_ 2358902526 Joystick1Lamp6Cmd "J1939-71";
BA_ "SigType" SG_ 2358902526 Joystick1Lamp5Cmd 5;
BA_ "SPN" SG_ 2358902526 Joystick1Lamp5Cmd 4464;
BA_ "SAEDocument" SG_ 2358902526 Joystick1Lamp5Cmd "J1939-71";
BA_ "SigType" SG_ 2358902526 Joystick1Lamp4Cmd 5;
BA_ "SPN" SG_ 2358902526 Joystick1Lamp4Cmd 4463;
BA_ "SAEDocument" SG_ 2358902526 Joystick1Lamp4Cmd "J1939-71";
BA_ "SigType" SG_ 2358902526 Joystick1Lamp3Cmd 5;
BA_ "SPN" SG_ 2358902526 Joystick1Lamp3Cmd 4462;
BA_ "SAEDocument" SG_ 2358902526 Joystick1Lamp3Cmd "J1939-71";
BA_ "SigType" SG_ 2358902526 Joystick1Lamp2Cmd 5;
BA_ "SPN" SG_ 2358902526 Joystick1Lamp2Cmd 4461;
BA_ "SAEDocument" SG_ 2358902526 Joystick1Lamp2Cmd "J1939-71";
BA_ "SigType" SG_ 2358902526 Joystick1Lamp1Cmd 5;
BA_ "SPN" SG_ 2358902526 Joystick1Lamp1Cmd 4460;
BA_ "SAEDocument" SG_ 2358902526 Joystick1Lamp1Cmd "J1939-71";
BA_ "SPN" SG_ 2348875518 MessageChecksum 4207;
BA_ "SAEDocument" SG_ 2348875518 MessageChecksum "J1939-71";
BA_ "SPN" SG_ 2348875518 MessageCounter 4206;
BA_ "SAEDocument" SG_ 2348875518 MessageCounter "J1939-71";
BA_ "SPN" SG_ 2348875518 EngRequestedTorqueHighResolution 4191;
BA_ "SAEDocument" SG_ 2348875518 EngRequestedTorqueHighResolution "J1939-71";
BA_ "SPN" SG_ 2348875518 TSC1CtrlPurpose 3350;
BA_ "SAEDocument" SG_ 2348875518 TSC1CtrlPurpose "J1939-71";
BA_ "SPN" SG_ 2348875518 TSC1TransRate 3349;
BA_ "SAEDocument" SG_ 2348875518 TSC1TransRate "J1939-71";
BA_ "SPN" SG_ 2348875518 EngRequestedTorque_TorqueLimit 518;
BA_ "SAEDocument" SG_ 2348875518 EngRequestedTorque_TorqueLimit "J1939-71";
BA_ "SPN" SG_ 2348875518 EngRequestedSpeed_SpeedLimit 898;
BA_ "SAEDocument" SG_ 2348875518 EngRequestedSpeed_SpeedLimit "J1939-71";
BA_ "SigType" SG_ 2348875518 OverrideCtrlModePriority 5;
BA_ "SPN" SG_ 2348875518 OverrideCtrlModePriority 897;
BA_ "SAEDocument" SG_ 2348875518 OverrideCtrlModePriority "J1939-71";
BA_ "SigType" SG_ 2348875518 EngRequestedSpeedCtrlConditions 5;
BA_ "SPN" SG_ 2348875518 EngRequestedSpeedCtrlConditions 696;
BA_ "SAEDocument" SG_ 2348875518 EngRequestedSpeedCtrlConditions "J1939-71";
BA_ "SigType" SG_ 2348875518 EngOverrideCtrlMode 5;
BA_ "SPN" SG_ 2348875518 EngOverrideCtrlMode 695;
BA_ "SAEDocument" SG_ 2348875518 EngOverrideCtrlMode "J1939-71";
BA_ "SigType" SG_ 2566802430 TransTorqueLimit 1;
BA_ "SPN" SG_ 2566802430 TransTorqueLimit 1845;
BA_ "SAEDocument" SG_ 2566802430 TransTorqueLimit "J1939-71";
BA_ "SPN" SG_ 2566841342 SupportTSC1CtrlPurposeGroup4 3348;
BA_ "SAEDocument" SG_ 2566841342 SupportTSC1CtrlPurposeGroup4 "J1939-71";
BA_ "SPN" SG_ 2566841342 SupportTSC1CtrlPurposeGroup3 3347;
BA_ "SAEDocument" SG_ 2566841342 SupportTSC1CtrlPurposeGroup3 "J1939-71";
BA_ "SPN" SG_ 2566841342 SupportTSC1CtrlPurposeGroup2 3346;
BA_ "SAEDocument" SG_ 2566841342 SupportTSC1CtrlPurposeGroup2 "J1939-71";
BA_ "SPN" SG_ 2566841342 SupportTSC1CtrlPurposeGroup1 3345;
BA_ "SAEDocument" SG_ 2566841342 SupportTSC1CtrlPurposeGroup1 "J1939-71";
BA_ "SPN" SG_ 2566841342 SupportVariableRateTSC1Message 3344;
BA_ "SAEDocument" SG_ 2566841342 SupportVariableRateTSC1Message "J1939-71";
BA_ "SigType" SG_ 2566841342 EngDefaultTorqueLimit 1;
BA_ "SPN" SG_ 2566841342 EngDefaultTorqueLimit 1846;
BA_ "SAEDocument" SG_ 2566841342 EngDefaultTorqueLimit "J1939-71";
BA_ "SPN" SG_ 2566841342 EngMomentOfInertia 1794;
BA_ "SAEDocument" SG_ 2566841342 EngMomentOfInertia "J1939-71";
BA_ "SigType" SG_ 2566841342 EngExRngRqstdSpdCtrlRngUpprLimit 1;
BA_ "SPN" SG_ 2566841342 EngExRngRqstdSpdCtrlRngUpprLimit 1712;
BA_ "SAEDocument" SG_ 2566841342 EngExRngRqstdSpdCtrlRngUpprLimit "J1939-71";
BA_ "SigType" SG_ 2566841342 EngRqstdTrqueCtrlRangeUpperLimit 1;
BA_ "SPN" SG_ 2566841342 EngRqstdTrqueCtrlRangeUpperLimit 538;
BA_ "SAEDocument" SG_ 2566841342 EngRqstdTrqueCtrlRangeUpperLimit "J1939-71";
BA_ "SigType" SG_ 2566841342 EngRqstdTrqueCtrlRangeLowerLimit 1;
BA_ "SPN" SG_ 2566841342 EngRqstdTrqueCtrlRangeLowerLimit 537;
BA_ "SAEDocument" SG_ 2566841342 EngRqstdTrqueCtrlRangeLowerLimit "J1939-71";
BA_ "SigType" SG_ 2566841342 EngRqstdSpeedCtrlRangeUpperLimit 1;
BA_ "SPN" SG_ 2566841342 EngRqstdSpeedCtrlRangeUpperLimit 536;
BA_ "SAEDocument" SG_ 2566841342 EngRqstdSpeedCtrlRangeUpperLimit "J1939-71";
BA_ "SigType" SG_ 2566841342 EngRqstdSpeedCtrlRangeLowerLimit 1;
BA_ "SPN" SG_ 2566841342 EngRqstdSpeedCtrlRangeLowerLimit 535;
BA_ "SAEDocument" SG_ 2566841342 EngRqstdSpeedCtrlRangeLowerLimit "J1939-71";
BA_ "SigType" SG_ 2566841342 EngMaxMomentaryOverrideTimeLimit 1;
BA_ "SPN" SG_ 2566841342 EngMaxMomentaryOverrideTimeLimit 534;
BA_ "SAEDocument" SG_ 2566841342 EngMaxMomentaryOverrideTimeLimit "J1939-71";
BA_ "SigType" SG_ 2566841342 EngMxMmentaryOverrideSpeedPoint7 1;
BA_ "SPN" SG_ 2566841342 EngMxMmentaryOverrideSpeedPoint7 533;
BA_ "SAEDocument" SG_ 2566841342 EngMxMmentaryOverrideSpeedPoint7 "J1939-71";
BA_ "SigType" SG_ 2566841342 EngReferenceTorque 1;
BA_ "SPN" SG_ 2566841342 EngReferenceTorque 544;
BA_ "SAEDocument" SG_ 2566841342 EngReferenceTorque "J1939-71";
BA_ "SigType" SG_ 2566841342 EngGain 1;
BA_ "SPN" SG_ 2566841342 EngGain 545;
BA_ "SAEDocument" SG_ 2566841342 EngGain "J1939-71";
BA_ "SigType" SG_ 2566841342 EngSpeedAtHighIdlePoint6 1;
BA_ "SPN" SG_ 2566841342 EngSpeedAtHighIdlePoint6 532;
BA_ "SAEDocument" SG_ 2566841342 EngSpeedAtHighIdlePoint6 "J1939-71";
BA_ "SigType" SG_ 2566841342 EngPercentTorqueAtPoint5 1;
BA_ "SPN" SG_ 2566841342 EngPercentTorqueAtPoint5 543;
BA_ "SAEDocument" SG_ 2566841342 EngPercentTorqueAtPoint5 "J1939-71";
BA_ "SigType" SG_ 2566841342 EngSpeedAtPoint5 1;
BA_ "SPN" SG_ 2566841342 EngSpeedAtPoint5 531;
BA_ "SAEDocument" SG_ 2566841342 EngSpeedAtPoint5 "J1939-71";
BA_ "SigType" SG_ 2566841342 EngPercentTorqueAtPoint4 1;
BA_ "SPN" SG_ 2566841342 EngPercentTorqueAtPoint4 542;
BA_ "SAEDocument" SG_ 2566841342 EngPercentTorqueAtPoint4 "J1939-71";
BA_ "SigType" SG_ 2566841342 EngSpeedAtPoint4 1;
BA_ "SPN" SG_ 2566841342 EngSpeedAtPoint4 530;
BA_ "SAEDocument" SG_ 2566841342 EngSpeedAtPoint4 "J1939-71";
BA_ "SigType" SG_ 2566841342 EngPercentTorqueAtPoint3 1;
BA_ "SPN" SG_ 2566841342 EngPercentTorqueAtPoint3 541;
BA_ "SAEDocument" SG_ 2566841342 EngPercentTorqueAtPoint3 "J1939-71";
BA_ "SigType" SG_ 2566841342 EngSpeedAtPoint3 1;
BA_ "SPN" SG_ 2566841342 EngSpeedAtPoint3 529;
BA_ "SAEDocument" SG_ 2566841342 EngSpeedAtPoint3 "J1939-71";
BA_ "SigType" SG_ 2566841342 EngPercentTorqueAtPoint2 1;
BA_ "SPN" SG_ 2566841342 EngPercentTorqueAtPoint2 540;
BA_ "SAEDocument" SG_ 2566841342 EngPercentTorqueAtPoint2 "J1939-71";
BA_ "SigType" SG_ 2566841342 EngSpeedAtPoint2 1;
BA_ "SPN" SG_ 2566841342 EngSpeedAtPoint2 528;
BA_ "SAEDocument" SG_ 2566841342 EngSpeedAtPoint2 "J1939-71";
BA_ "SigType" SG_ 2566841342 EngPercentTorqueAtIdlePoint1 1;
BA_ "SPN" SG_ 2566841342 EngPercentTorqueAtIdlePoint1 539;
BA_ "SAEDocument" SG_ 2566841342 EngPercentTorqueAtIdlePoint1 "J1939-71";
BA_ "SigType" SG_ 2566841342 EngSpeedAtIdlePoint1 1;
BA_ "SPN" SG_ 2566841342 EngSpeedAtIdlePoint1 188;
BA_ "SAEDocument" SG_ 2566841342 EngSpeedAtIdlePoint1 "J1939-71";
BA_ "SAEDocument" SG_ 2564030206 CalibrationID4 "J1939-73";
BA_ "SAEDocument" SG_ 2564030206 CalibrationID3 "J1939-73";
BA_ "SAEDocument" SG_ 2564030206 CalibrationID2 "J1939-73";
BA_ "SPN" SG_ 2564030206 CalibrationID1 1635;
BA_ "SAEDocument" SG_ 2564030206 CalibrationID1 "J1939-73";
BA_ "SigType" SG_ 2564030206 CalibrationVerificationNumber 1;
BA_ "SPN" SG_ 2564030206 CalibrationVerificationNumber 1634;
BA_ "SAEDocument" SG_ 2564030206 CalibrationVerificationNumber "J1939-73";
VAL_ 3221225472 DslPrtcltFltrActvRgnrtnInhbtdDTE 3 "notAvailable" 2 "reservedForSAEAssignment" 1 "inhibited" 0 "notInhibited" ;
VAL_ 2348941054 TransMode8 3 "Take no action" 2 "Reserved" 1 "Enable" 0 "Disable" ;
VAL_ 2348941054 TransMode7 3 "Take no action" 2 "Reserved" 1 "Enable" 0 "Disable" ;
VAL_ 2348941054 TransMode6 3 "Take no action" 2 "Reserved" 1 "Enable" 0 "Disable" ;
VAL_ 2348941054 TransMode5 3 "Take no action" 2 "Reserved" 1 "Enable" 0 "Disable" ;
VAL_ 2348941054 TrnsShftSlectorDisplayModeSwitch 3 "Not available" 2 "Error" 1 "On" 0 "Off" ;
VAL_ 2348941054 TransRequestedLaunchGear 15 "Not Available" 14 "Error" 13 "Reserved" 12 "Launch the vehicle in Reverse 4" 11 "Launch the vehicle in Reverse 3" 10 "Launch the vehicle in Reverse 2" 9 "Launch the vehicle in Reverse 1" 8 "Launch the vehicle in 8th gear" 7 "Launch the vehicle in 7th gear" 6 "Launch the vehicle in 6th gear" 5 "Launch the vehicle in 5th gear" 4 "Launch the vehicle in 4th gear" 3 "Launch the vehicle in 3rd gear" 2 "Launch the vehicle in 2nd gear" 1 "Launch the vehicle in 1st gear" 0 "No specific launch gear requested use default launch gear" ;
VAL_ 2348941054 TransMode4 3 "Take no action" 2 "Reserved" 1 "Enable" 0 "Disable" ;
VAL_ 2348941054 TransMode3 3 "Take no action" 2 "Reserved" 1 "Enable" 0 "Disable" ;
VAL_ 2348941054 TransMode2 3 "Take no action" 2 "Reserved" 1 "Enable" 0 "Disable" ;
VAL_ 2348941054 TransMode1 3 "Take no action" 2 "Reserved" 1 "Enable" 0 "Disable" ;
VAL_ 2348941054 DisengageDiffLockRqCentralRear 3 "Take no action" 2 "Reserved" 1 "Disengage differential lock" 0 "Engage differential lock" ;
VAL_ 2348941054 DisengageDiffLockRqCentralFront 3 "Take no action" 2 "Reserved" 1 "Disengage differential lock" 0 "Engage differential lock" ;
VAL_ 2348941054 DisengageDiffLockRqCentral 3 "Take no action" 2 "Reserved" 1 "Disengage differential lock" 0 "Engage differential lock" ;
VAL_ 2348941054 DisengageDiffLockRqRearAxle2 3 "Take no action" 2 "Reserved" 1 "Disengage differential lock" 0 "Engage differential lock" ;
VAL_ 2348941054 DisengageDiffLockRqRearAxle1 3 "Take no action" 2 "Reserved" 1 "Disengage differential lock" 0 "Engage differential lock" ;
VAL_ 2348941054 DisengageDiffLockRqFrontAxle2 3 "Take no action" 2 "Reserved" 1 "Disengage differential lock" 0 "Engage differential lock" ;
VAL_ 2348941054 DisengageDiffLockRqFrontAxle1 3 "Take no action" 2 "Reserved" 1 "Disengage differential lock" 0 "Engage differential lock" ;
VAL_ 2348941054 TransReverseGearShiftInhibitRq 3 "Take no action" 2 "Reserved" 1 "Inhibit shifts into Reverse gear and shift transmission to Neutral if already in Reverse or attempting to shift to" 0 "Allow shifts into Reverse gear" ;
VAL_ 2348941054 DisengageDrivelineRq 2 "Reserved" 3 "Take no action" 1 "Disengage driveline" 0 "Allow driveline engagement" ;
VAL_ 2348941054 TrnsTrqeConverterLockupDisableRq 3 "Take no action" 2 "Reserved" 1 "Disable torque converter lockup" 0 "Allow torque converter lockup" ;
VAL_ 2348941054 TransGearShiftInhibitRq 2 "Reserved" 3 "Take no action leave function as is" 1 "Gear shifts are inhibited enable function" 0 "Gear shifts are allowed disable function" ;
VAL_ 2358902526 Joystick3Lamp10Cmd 3 "Not available or not installed" 2 "Blinking" 1 "On" 0 "Off" ;
VAL_ 2358902526 Joystick3Lamp9Cmd 3 "Not available or not installed" 2 "Blinking" 1 "On" 0 "Off" ;
VAL_ 2358902526 Joystick3Lamp8Cmd 3 "Not available or not installed" 2 "Blinking" 1 "On" 0 "Off" ;
VAL_ 2358902526 Joystick3Lamp7Cmd 3 "Not available or not installed" 2 "Blinking" 1 "On" 0 "Off" ;
VAL_ 2358902526 Joystick3Lamp6Cmd 3 "Not available or not installed" 2 "Blinking" 1 "On" 0 "Off" ;
VAL_ 2358902526 Joystick3Lamp5Cmd 3 "Not available or not installed" 2 "Blinking" 1 "On" 0 "Off" ;
VAL_ 2358902526 Joystick3Lamp4Cmd 3 "Not available or not installed" 2 "Blinking" 1 "On" 0 "Off" ;
VAL_ 2358902526 Joystick3Lamp3Cmd 3 "Not available or not installed" 2 "Blinking" 1 "On" 0 "Off" ;
VAL_ 2358902526 Joystick3Lamp2Cmd 3 "Not available or not installed" 2 "Blinking" 1 "On" 0 "Off" ;
VAL_ 2358902526 Joystick3Lamp1Cmd 3 "Not available or not installed" 2 "Blinking" 1 "On" 0 "Off" ;
VAL_ 2358902526 Joystick2Lamp10Cmd 3 "Not available or not installed" 2 "Blinking" 1 "On" 0 "Off" ;
VAL_ 2358902526 Joystick2Lamp9Cmd 3 "Not available or not installed" 2 "Blinking" 1 "On" 0 "Off" ;
VAL_ 2358902526 Joystick2Lamp8Cmd 3 "Not available or not installed" 2 "Blinking" 1 "On" 0 "Off" ;
VAL_ 2358902526 Joystick2Lamp7Cmd 3 "Not available or not installed" 2 "Blinking" 1 "On" 0 "Off" ;
VAL_ 2358902526 Joystick2Lamp6Cmd 3 "Not available or not installed" 2 "Blinking" 1 "On" 0 "Off" ;
VAL_ 2358902526 Joystick2Lamp5Cmd 3 "Not available or not installed" 2 "Blinking" 1 "On" 0 "Off" ;
VAL_ 2358902526 Joystick2Lamp4Cmd 3 "Not available or not installed" 2 "Blinking" 1 "On" 0 "Off" ;
VAL_ 2358902526 Joystick2Lamp3Cmd 3 "Not available or not installed" 2 "Blinking" 1 "On" 0 "Off" ;
VAL_ 2358902526 Joystick2Lamp2Cmd 3 "Not available or not installed" 2 "Blinking" 1 "On" 0 "Off" ;
VAL_ 2358902526 Joystick2Lamp1Cmd 3 "Not available or not installed" 2 "Blinking" 1 "On" 0 "Off" ;
VAL_ 2358902526 Joystick1Lamp10Cmd 3 "Not available or not installed" 2 "Blinking" 1 "On" 0 "Off" ;
VAL_ 2358902526 Joystick1Lamp9Cmd 3 "Not available or not installed" 2 "Blinking" 1 "On" 0 "Off" ;
VAL_ 2358902526 Joystick1Lamp8Cmd 3 "Not available or not installed" 2 "Blinking" 1 "On" 0 "Off" ;
VAL_ 2358902526 Joystick1Lamp7Cmd 3 "Not available or not installed" 2 "Blinking" 1 "On" 0 "Off" ;
VAL_ 2358902526 Joystick1Lamp6Cmd 3 "Not available or not installed" 2 "Blinking" 1 "On" 0 "Off" ;
VAL_ 2358902526 Joystick1Lamp5Cmd 3 "Not available or not installed" 2 "Blinking" 1 "On" 0 "Off" ;
VAL_ 2358902526 Joystick1Lamp4Cmd 3 "Not available or not installed" 2 "Blinking" 1 "On" 0 "Off" ;
VAL_ 2358902526 Joystick1Lamp3Cmd 3 "Not available or not installed" 2 "Blinking" 1 "On" 0 "Off" ;
VAL_ 2358902526 Joystick1Lamp2Cmd 3 "Not available or not installed" 2 "Blinking" 1 "On" 0 "Off" ;
VAL_ 2358902526 Joystick1Lamp1Cmd 3 "Not available or not installed" 2 "Blinking" 1 "On" 0 "Off" ;
VAL_ 2348875518 EngRequestedTorqueHighResolution 7 "0875" 1 "0125" 0 "0000" 8 "1111  not available" ;
VAL_ 2348875518 TSC1CtrlPurpose 31 "P32  Temporary Power Train Control Original use of TSC1 Command" 5 "11110  P6P31  Reserved for SAE Assignment" 4 "P5  Engine Protection" 3 "P4  Road Speed Governor" 2 "P3  PTO Governor" 1 "P2  Cruise Control" 0 "P1  Accelerator Pedal/Operator Selection" ;
VAL_ 2348875518 TSC1TransRate 7 "Use standard TSC1 transmission rates of 10 ms to engine" 6 "20 ms transmission rate" 5 "50 ms transmission rate" 4 "100 ms transmission rate" 3 "250 ms transmission rate" 2 "500 ms transmission rate" 1 "750 ms transmission rate" 0 "1000 ms transmission rate" ;
VAL_ 2348875518 OverrideCtrlModePriority 3 "Low priority" 2 "Medium priority" 1 "High priority" 0 "Highest priority" ;
VAL_ 2348875518 EngRequestedSpeedCtrlConditions 2 "Stability Optimized for driveline engaged and/or in lockup condition 1 eg vehicle driveline" 3 "Stability Optimized for driveline engaged and/or in lockup condition 2 eg PTO driveline" 1 "Stability Optimized for driveline disengaged and nonlockup conditions" 0 "Transient Optimized for driveline disengaged and nonlockup conditions" ;
VAL_ 2348875518 EngOverrideCtrlMode 3 "Speed/torque limit control  Limit speed and/or torque based on the included limit values The speed limit governor is" 2 "Torque control  Control torque to the included desired torque value" 1 "Speed control  Govern speed to the included desired speed value" 0 "Override disabled  Disable any existing control commanded by the source of this command" ;
